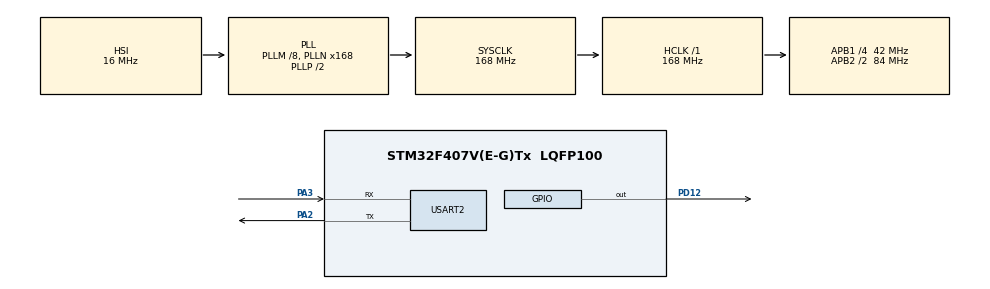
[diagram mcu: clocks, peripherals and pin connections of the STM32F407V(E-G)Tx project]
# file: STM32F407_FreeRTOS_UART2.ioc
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FREERTOS.Tasks01=defaultTask,0,128,StartDefaultTask,Default,NULL
Mcu.Family=STM32F4
Mcu.Name=STM32F407V(E-G)Tx
Mcu.Package=LQFP100
NVIC.PriorityGroup=NVIC_PRIORITYGROUP_4
PA2.Mode=Asynchronous
PA2.Signal=USART2_TX
PA3.Mode=Asynchronous
PA3.Signal=USART2_RX
PD12.Signal=GPIO_Output
PH0-OSC_IN.Mode=HSE-External-Oscillator
PH0-OSC_IN.Signal=RCC_OSC_IN
PH1-OSC_OUT.Mode=HSE-External-Oscillator
PH1-OSC_OUT.Signal=RCC_OSC_OUT
ProjectManager.HeapSize=0x200
ProjectManager.StackSize=0x400
ProjectManager.TargetToolchain=TrueSTUDIO
RCC.48MHZClocksFreq_Value=84000000
RCC.AHBFreq_Value=168000000
RCC.APB1CLKDivider=RCC_HCLK_DIV4
RCC.APB1Freq_Value=42000000
RCC.APB1TimFreq_Value=84000000
RCC.APB2CLKDivider=RCC_HCLK_DIV2
RCC.APB2Freq_Value=84000000
RCC.APB2TimFreq_Value=168000000
RCC.CortexFreq_Value=168000000
RCC.HCLKFreq_Value=168000000
RCC.HSE_VALUE=8000000
RCC.HSI_VALUE=16000000
RCC.LSE_VALUE=32768
RCC.PLLM=8
RCC.PLLN=168
RCC.SYSCLKFreq_VALUE=168000000
RCC.SYSCLKSource=RCC_SYSCLKSOURCE_PLLCLK
RCC.VCOOutputFreq_Value=336000000
USART2.VirtualMode=VM_ASYNC
VP_FREERTOS_VS_ENABLE.Mode=Enabled
VP_TIM6_VS_ClockSourceINT.Mode=Enable_Timer
board=STM32F407_FreeRTOS_UART2

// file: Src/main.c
/**
  ******************************************************************************
  * File Name          : main.c
  * Description        : Main program body
  ******************************************************************************
  * This notice applies to any and all portions of this file
  * that are not between comment pairs USER CODE BEGIN and
  * USER CODE END. Other portions of this file, whether
  * inserted by the user or by software development tools
  * are owned by their respective copyright owners.
  *
  * Copyright (c) 2020 STMicroelectronics International N.V.
  * All rights reserved.
  *
  * Redistribution and use in source and binary forms, with or without
  * modification, are permitted, provided that the following conditions are met:
  *
  * 1. Redistribution of source code must retain the above copyright notice,
  *    this list of conditions and the following disclaimer.
  * 2. Redistributions in binary form must reproduce the above copyright notice,
  *    this list of conditions and the following disclaimer in the documentation
  *    and/or other materials provided with the distribution.
  * 3. Neither the name of STMicroelectronics nor the names of other
  *    contributors to this software may be used to endorse or promote products
  *    derived from this software without specific written permission.
  * 4. This software, including modifications and/or derivative works of this
  *    software, must execute solely and exclusively on microcontroller or
  *    microprocessor devices manufactured by or for STMicroelectronics.
  * 5. Redistribution and use of this software other than as permitted under
  *    this license is void and will automatically terminate your rights under
  *    this license.
  *
  * THIS SOFTWARE IS PROVIDED BY STMICROELECTRONICS AND CONTRIBUTORS "AS IS"
  * AND ANY EXPRESS, IMPLIED OR STATUTORY WARRANTIES, INCLUDING, BUT NOT
  * LIMITED TO, THE IMPLIED WARRANTIES OF MERCHANTABILITY, FITNESS FOR A
  * PARTICULAR PURPOSE AND NON-INFRINGEMENT OF THIRD PARTY INTELLECTUAL PROPERTY
  * RIGHTS ARE DISCLAIMED TO THE FULLEST EXTENT PERMITTED BY LAW. IN NO EVENT
  * SHALL STMICROELECTRONICS OR CONTRIBUTORS BE LIABLE FOR ANY DIRECT, INDIRECT,
  * INCIDENTAL, SPECIAL, EXEMPLARY, OR CONSEQUENTIAL DAMAGES (INCLUDING, BUT NOT
  * LIMITED TO, PROCUREMENT OF SUBSTITUTE GOODS OR SERVICES; LOSS OF USE, DATA,
  * OR PROFITS; OR BUSINESS INTERRUPTION) HOWEVER CAUSED AND ON ANY THEORY OF
  * LIABILITY, WHETHER IN CONTRACT, STRICT LIABILITY, OR TORT (INCLUDING
  * NEGLIGENCE OR OTHERWISE) ARISING IN ANY WAY OUT OF THE USE OF THIS SOFTWARE,
  * EVEN IF ADVISED OF THE POSSIBILITY OF SUCH DAMAGE.
  *
  ******************************************************************************
  */

#include "main.h"
#include "stm32f4xx_hal.h"
#include "cmsis_os.h"

TIM_HandleTypeDef htim6;

UART_HandleTypeDef huart2;

osThreadId defaultTaskHandle;

/* USER CODE BEGIN PV */
/* Private variables ---------------------------------------------------------*/

/* USER CODE END PV */

void SystemClock_Config(void);
static void MX_GPIO_Init(void);
static void MX_TIM6_Init(void);
static void MX_USART2_UART_Init(void);
void StartDefaultTask(void const * argument);

/* USER CODE BEGIN PFP */
/* Private function prototypes -----------------------------------------------*/

/* USER CODE END PFP */

/* USER CODE BEGIN 0 */

/* Task 1. */
void main_task1() {
	int i = 0;
	uint8_t str[] = "Hello world! i\r\n";
	uint16_t Size = strlen(str);
	uint32_t Timeout = 500;

	while(1) {
		str[13] = i + '0';

		HAL_UART_Transmit(&huart2, str, Size, Timeout);
		i = (i + 1) % 10;
//		HAL_Delay(500);
		vTaskDelay(1);
	}
}

/* Task 2. */
void main_task2() {
	int i = 0;
	uint8_t str[] = "Go Go i! Then ...\r\n";
	uint16_t Size = strlen(str);
	uint32_t Timeout = 500;

	while(1) {
		str[6] = i + '0';

		HAL_UART_Transmit(&huart2, str, Size, Timeout);
		i = (i + 1) % 10;
//		HAL_Delay(500);
		vTaskDelay(1);
	}
}

/* USER CODE END 0 */

int main(void)
{

  /* MCU Configuration----------------------------------------------------------*/

  /* Reset of all peripherals, Initializes the Flash interface and the Systick. */
  HAL_Init();

  /* Configure the system clock */
  SystemClock_Config();

  /* Initialize all configured peripherals */
  MX_GPIO_Init();
  MX_TIM6_Init();
  MX_USART2_UART_Init();

  /* Create the thread(s) */
  /* definition and creation of defaultTask */
  osThreadDef(defaultTask, StartDefaultTask, osPriorityNormal, 0, 128);
  defaultTaskHandle = osThreadCreate(osThread(defaultTask), NULL);

  /* USER CODE BEGIN RTOS_THREADS */
  /* add threads, ... */

  /* Add the main task into FreeRTOS task scheduler. */
  	xTaskCreate(main_task1, "Main Task1", 512, NULL, 1, NULL);
  	xTaskCreate(main_task2, "Main Task2", 512, NULL, 0, NULL);

  	/* Start FreeRTOS task scheduler. */
  		vTaskStartScheduler();

  /* USER CODE END RTOS_THREADS */

  /* Start scheduler */
  osKernelStart();

  /* We should never get here as control is now taken by the scheduler */

  /* Infinite loop */
  while (1)
  {

  }

}

/** System Clock Configuration
*/
void SystemClock_Config(void)
{

  RCC_OscInitTypeDef RCC_OscInitStruct;
  RCC_ClkInitTypeDef RCC_ClkInitStruct;

    /**Configure the main internal regulator output voltage
    */
  __HAL_RCC_PWR_CLK_ENABLE();

  __HAL_PWR_VOLTAGESCALING_CONFIG(PWR_REGULATOR_VOLTAGE_SCALE1);

    /**Initializes the CPU, AHB and APB busses clocks
    */
  RCC_OscInitStruct.OscillatorType = RCC_OSCILLATORTYPE_HSI;
  RCC_OscInitStruct.HSIState = RCC_HSI_ON;
  RCC_OscInitStruct.HSICalibrationValue = 16;
  RCC_OscInitStruct.PLL.PLLState = RCC_PLL_ON;
  RCC_OscInitStruct.PLL.PLLSource = RCC_PLLSOURCE_HSI;
  RCC_OscInitStruct.PLL.PLLM = 8;
  RCC_OscInitStruct.PLL.PLLN = 168;
  RCC_OscInitStruct.PLL.PLLP = RCC_PLLP_DIV2;
  RCC_OscInitStruct.PLL.PLLQ = 4;
  if (HAL_RCC_OscConfig(&RCC_OscInitStruct) != HAL_OK)
  {
    _Error_Handler(__FILE__, __LINE__);
  }

    /**Initializes the CPU, AHB and APB busses clocks
    */
  RCC_ClkInitStruct.ClockType = RCC_CLOCKTYPE_HCLK|RCC_CLOCKTYPE_SYSCLK
                              |RCC_CLOCKTYPE_PCLK1|RCC_CLOCKTYPE_PCLK2;
  RCC_ClkInitStruct.SYSCLKSource = RCC_SYSCLKSOURCE_PLLCLK;
  RCC_ClkInitStruct.AHBCLKDivider = RCC_SYSCLK_DIV1;
  RCC_ClkInitStruct.APB1CLKDivider = RCC_HCLK_DIV4;
  RCC_ClkInitStruct.APB2CLKDivider = RCC_HCLK_DIV2;

  if (HAL_RCC_ClockConfig(&RCC_ClkInitStruct, FLASH_LATENCY_5) != HAL_OK)
  {
    _Error_Handler(__FILE__, __LINE__);
  }

    /**Configure the Systick interrupt time
    */
  HAL_SYSTICK_Config(HAL_RCC_GetHCLKFreq()/1000);

    /**Configure the Systick
    */
  HAL_SYSTICK_CLKSourceConfig(SYSTICK_CLKSOURCE_HCLK);

  /* SysTick_IRQn interrupt configuration */
  HAL_NVIC_SetPriority(SysTick_IRQn, 15, 0);
}

/* TIM6 init function */
static void MX_TIM6_Init(void)
{

  TIM_MasterConfigTypeDef sMasterConfig;

  htim6.Instance = TIM6;
  htim6.Init.Prescaler = 0;
  htim6.Init.CounterMode = TIM_COUNTERMODE_UP;
  htim6.Init.Period = 0;
  if (HAL_TIM_Base_Init(&htim6) != HAL_OK)
  {
    _Error_Handler(__FILE__, __LINE__);
  }

  sMasterConfig.MasterOutputTrigger = TIM_TRGO_RESET;
  sMasterConfig.MasterSlaveMode = TIM_MASTERSLAVEMODE_DISABLE;
  if (HAL_TIMEx_MasterConfigSynchronization(&htim6, &sMasterConfig) != HAL_OK)
  {
    _Error_Handler(__FILE__, __LINE__);
  }

}

/* USART2 init function */
static void MX_USART2_UART_Init(void)
{

  huart2.Instance = USART2;
  huart2.Init.BaudRate = 115200;
  huart2.Init.WordLength = UART_WORDLENGTH_8B;
  huart2.Init.StopBits = UART_STOPBITS_1;
  huart2.Init.Parity = UART_PARITY_NONE;
  huart2.Init.Mode = UART_MODE_TX_RX;
  huart2.Init.HwFlowCtl = UART_HWCONTROL_NONE;
  huart2.Init.OverSampling = UART_OVERSAMPLING_16;
  if (HAL_UART_Init(&huart2) != HAL_OK)
  {
    _Error_Handler(__FILE__, __LINE__);
  }

}

/** Configure pins as
        * Analog
        * Input
        * Output
        * EVENT_OUT
        * EXTI
*/
static void MX_GPIO_Init(void)
{

  GPIO_InitTypeDef GPIO_InitStruct;

  /* GPIO Ports Clock Enable */
  __HAL_RCC_GPIOH_CLK_ENABLE();
  __HAL_RCC_GPIOA_CLK_ENABLE();
  __HAL_RCC_GPIOD_CLK_ENABLE();

  /*Configure GPIO pin Output Level */
  HAL_GPIO_WritePin(GPIOD, GPIO_PIN_12, GPIO_PIN_RESET);

  /*Configure GPIO pin : PD12 */
  GPIO_InitStruct.Pin = GPIO_PIN_12;
  GPIO_InitStruct.Mode = GPIO_MODE_OUTPUT_PP;
  GPIO_InitStruct.Pull = GPIO_NOPULL;
  GPIO_InitStruct.Speed = GPIO_SPEED_FREQ_LOW;
  HAL_GPIO_Init(GPIOD, &GPIO_InitStruct);

}

/* StartDefaultTask function */
void StartDefaultTask(void const * argument)
{

  for(;;)
  {
    osDelay(1);
  }
}

void _Error_Handler(char * file, int line)
{
  while(1)
  {
  }
}

/************************ (C) COPYRIGHT STMicroelectronics *****END OF FILE****/
